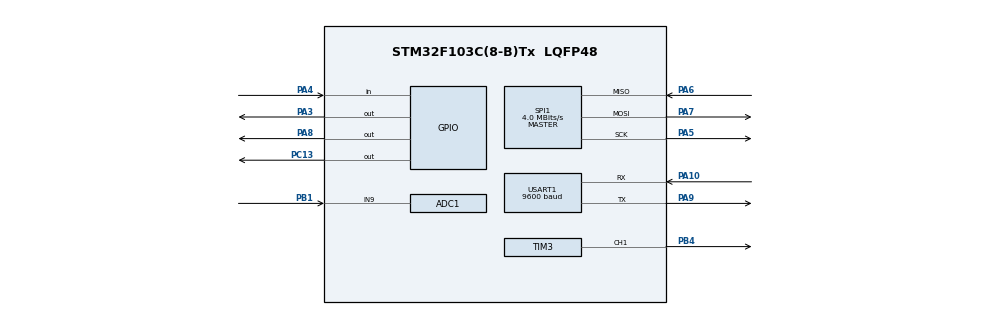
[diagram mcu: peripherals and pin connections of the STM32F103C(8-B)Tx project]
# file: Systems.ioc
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ADC1.Channel-0\#ChannelRegularConversion=ADC_CHANNEL_9
ADC1.NbrOfConversionFlag=1
ADC1.Rank-0\#ChannelRegularConversion=1
ADC1.SamplingTime-0\#ChannelRegularConversion=ADC_SAMPLETIME_1CYCLE_5
ADC1.master=1
Mcu.Family=STM32F1
Mcu.Name=STM32F103C(8-B)Tx
Mcu.Package=LQFP48
NVIC.PriorityGroup=NVIC_PRIORITYGROUP_4
NVIC.TIM1_UP_IRQn=true\:15\:0\:false\:false\:true\:false\:true
NVIC.TimeBase=TIM1_UP_IRQn
NVIC.TimeBaseIP=TIM1
PA10.Mode=Asynchronous
PA10.Signal=USART1_RX
PA13.Mode=Serial_Wire
PA13.Signal=SYS_JTMS-SWDIO
PA14.Mode=Serial_Wire
PA14.Signal=SYS_JTCK-SWCLK
PA3.Signal=GPIO_Output
PA4.Signal=GPIO_Input
PA5.Mode=Full_Duplex_Master
PA5.Signal=SPI1_SCK
PA6.Mode=Full_Duplex_Master
PA6.Signal=SPI1_MISO
PA7.Mode=Full_Duplex_Master
PA7.Signal=SPI1_MOSI
PA8.Signal=GPIO_Output
PA9.Mode=Asynchronous
PA9.Signal=USART1_TX
PB0.Signal=S_TIM3_CH3
PB1.Signal=ADCx_IN9
PB4.Signal=S_TIM3_CH1
PC13-TAMPER-RTC.Signal=GPIO_Output
ProjectManager.HeapSize=0x200
ProjectManager.StackSize=0x400
ProjectManager.TargetToolchain=STM32CubeIDE
RCC.APB1Freq_Value=8000000
RCC.APB2Freq_Value=8000000
SH.ADCx_IN9.0=ADC1_IN9,IN9
SH.S_TIM3_CH1.0=TIM3_CH1,PWM Generation1 CH1
SH.S_TIM3_CH3.0=TIM3_CH3
SPI1.CalculateBaudRate=4.0 MBits/s
SPI1.Direction=SPI_DIRECTION_2LINES
SPI1.Mode=SPI_MODE_MASTER
SPI1.VirtualType=VM_MASTER
TIM2.Prescaler=7
TIM3.Channel-PWM\ Generation1\ CH1=TIM_CHANNEL_1
TIM3.CounterMode=TIM_COUNTERMODE_DOWN
TIM3.Period=255
TIM3.Prescaler=7
TIM4.CounterMode=TIM_COUNTERMODE_DOWN
TIM4.Prescaler=7999
USART1.BaudRate=9600
USART1.VirtualMode=VM_ASYNC
VP_SYS_VS_tim1.Mode=TIM1
VP_TIM2_VS_ClockSourceINT.Mode=Internal
VP_TIM3_VS_ClockSourceINT.Mode=Internal
VP_TIM4_VS_ClockSourceINT.Mode=Internal
board=custom

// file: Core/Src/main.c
/* USER CODE BEGIN Header */
/**
  ******************************************************************************
  * @file           : main.c
  * @brief          : Main program body
  ******************************************************************************
  * @attention
  *
  * <h2><center>&copy; Copyright (c) 2022 STMicroelectronics.
  * All rights reserved.</center></h2>
  *
  * This software component is licensed by ST under BSD 3-Clause license,
  * the "License"; You may not use this file except in compliance with the
  * License. You may obtain a copy of the License at:
  *                        opensource.org/licenses/BSD-3-Clause
  *
  ******************************************************************************
  */
/* USER CODE END Header */
#include "main.h"

/* USER CODE BEGIN Includes */
#include <string.h>
#include <stdio.h>
#include "ultrasonic.h"
#include "PWM.h"
/* USER CODE END Includes */

ADC_HandleTypeDef hadc1;

SPI_HandleTypeDef hspi1;

TIM_HandleTypeDef htim2;
TIM_HandleTypeDef htim3;
TIM_HandleTypeDef htim4;

UART_HandleTypeDef huart1;

void SystemClock_Config(void);
static void MX_GPIO_Init(void);
static void MX_SPI1_Init(void);
static void MX_TIM3_Init(void);
static void MX_USART1_UART_Init(void);
static void MX_ADC1_Init(void);
static void MX_TIM2_Init(void);
static void MX_TIM4_Init(void);

/* USER CODE BEGIN 0 */
uint16_t readValue;
/* USER CODE END 0 */

int main(void)
{
  /* USER CODE BEGIN 1 */
  char msg[10];
  /* USER CODE END 1 */

  /* MCU Configuration--------------------------------------------------------*/

  /* Reset of all peripherals, Initializes the Flash interface and the Systick. */
  HAL_Init();

  /* Configure the system clock */
  SystemClock_Config();

  /* Initialize all configured peripherals */
  MX_GPIO_Init();
  MX_SPI1_Init();
  MX_TIM3_Init();
  MX_USART1_UART_Init();
  MX_ADC1_Init();
  MX_TIM2_Init();
  MX_TIM4_Init();
  /* USER CODE BEGIN 2 */
  US_vidInit(&htim2);

  //  PWM_vidInit(&htim3, TIM_CHANNEL_3);
  //HAL_TIM_PWM_Start(&htim3, TIM_CHANNEL_3);

  /* USER CODE END 2 */

  /* Infinite loop */
  /* USER CODE BEGIN WHILE */
  while (1)
  {

    /*
	     sprintf(msg, "%hu\r\n",Value1);
	      HAL_UART_Transmit(&huart1, (uint8_t *)msg, strlen(msg), HAL_MAX_DELAY);
	      HAL_Delay(1);
	      sprintf(msg, "%hu\r\n",Value2);
	     	      HAL_UART_Transmit(&huart1, (uint8_t *)msg, strlen(msg), HAL_MAX_DELAY);
	        HAL_Delay(1);
*/

    //  PWM_vidStart(50);
    //uint8_t RxByte  ;
    uint8_t TxByte = US_u8CalculateDistance();
    //	        HAL_GPIO_WritePin(GPIOA, GPIO_PIN_8, GPIO_PIN_RESET);
    //	            HAL_SPI_TransmitReceive(&hspi1, &TxByte, &RxByte, 1, HAL_MAX_DELAY);
    //
    //	            HAL_GPIO_WritePin(GPIOA, GPIO_PIN_8, GPIO_PIN_SET);
    //	     sprintf(msg, "%hu\r\n",RxByte);
    sprintf(msg, "%hu\r\n", TxByte);
    HAL_UART_Transmit(&huart1, (uint8_t *)msg, strlen(msg), HAL_MAX_DELAY);
    HAL_Delay(1000);

    //	     dutyCycle =(uint16_t) (255 * 20)/100;
    //
    //	     __HAL_TIM_SET_COMPARE(&htim3, TIM_CHANNEL_3, dutyCycle);
    HAL_GPIO_TogglePin(GPIOC, GPIO_PIN_13);

    /* USER CODE END WHILE */

  }
}

void SystemClock_Config(void)
{
  RCC_OscInitTypeDef RCC_OscInitStruct = {0};
  RCC_ClkInitTypeDef RCC_ClkInitStruct = {0};
  RCC_PeriphCLKInitTypeDef PeriphClkInit = {0};

  /** Initializes the RCC Oscillators according to the specified parameters
  * in the RCC_OscInitTypeDef structure.
  */
  RCC_OscInitStruct.OscillatorType = RCC_OSCILLATORTYPE_HSI;
  RCC_OscInitStruct.HSIState = RCC_HSI_ON;
  RCC_OscInitStruct.HSICalibrationValue = RCC_HSICALIBRATION_DEFAULT;
  RCC_OscInitStruct.PLL.PLLState = RCC_PLL_NONE;
  if (HAL_RCC_OscConfig(&RCC_OscInitStruct) != HAL_OK)
  {
    Error_Handler();
  }
  /** Initializes the CPU, AHB and APB buses clocks
  */
  RCC_ClkInitStruct.ClockType = RCC_CLOCKTYPE_HCLK | RCC_CLOCKTYPE_SYSCLK | RCC_CLOCKTYPE_PCLK1 | RCC_CLOCKTYPE_PCLK2;
  RCC_ClkInitStruct.SYSCLKSource = RCC_SYSCLKSOURCE_HSI;
  RCC_ClkInitStruct.AHBCLKDivider = RCC_SYSCLK_DIV1;
  RCC_ClkInitStruct.APB1CLKDivider = RCC_HCLK_DIV1;
  RCC_ClkInitStruct.APB2CLKDivider = RCC_HCLK_DIV1;

  if (HAL_RCC_ClockConfig(&RCC_ClkInitStruct, FLASH_LATENCY_0) != HAL_OK)
  {
    Error_Handler();
  }
  PeriphClkInit.PeriphClockSelection = RCC_PERIPHCLK_ADC;
  PeriphClkInit.AdcClockSelection = RCC_ADCPCLK2_DIV2;
  if (HAL_RCCEx_PeriphCLKConfig(&PeriphClkInit) != HAL_OK)
  {
    Error_Handler();
  }
}

static void MX_ADC1_Init(void)
{

  ADC_ChannelConfTypeDef sConfig = {0};

  /** Common config
  */
  hadc1.Instance = ADC1;
  hadc1.Init.ScanConvMode = ADC_SCAN_DISABLE;
  hadc1.Init.ContinuousConvMode = DISABLE;
  hadc1.Init.DiscontinuousConvMode = DISABLE;
  hadc1.Init.ExternalTrigConv = ADC_SOFTWARE_START;
  hadc1.Init.DataAlign = ADC_DATAALIGN_RIGHT;
  hadc1.Init.NbrOfConversion = 1;
  if (HAL_ADC_Init(&hadc1) != HAL_OK)
  {
    Error_Handler();
  }
  /** Configure Regular Channel
  */
  sConfig.Channel = ADC_CHANNEL_9;
  sConfig.Rank = ADC_REGULAR_RANK_1;
  sConfig.SamplingTime = ADC_SAMPLETIME_1CYCLE_5;
  if (HAL_ADC_ConfigChannel(&hadc1, &sConfig) != HAL_OK)
  {
    Error_Handler();
  }
}

static void MX_SPI1_Init(void)
{

  /* SPI1 parameter configuration*/
  hspi1.Instance = SPI1;
  hspi1.Init.Mode = SPI_MODE_MASTER;
  hspi1.Init.Direction = SPI_DIRECTION_2LINES;
  hspi1.Init.DataSize = SPI_DATASIZE_8BIT;
  hspi1.Init.CLKPolarity = SPI_POLARITY_LOW;
  hspi1.Init.CLKPhase = SPI_PHASE_1EDGE;
  hspi1.Init.NSS = SPI_NSS_SOFT;
  hspi1.Init.BaudRatePrescaler = SPI_BAUDRATEPRESCALER_2;
  hspi1.Init.FirstBit = SPI_FIRSTBIT_MSB;
  hspi1.Init.TIMode = SPI_TIMODE_DISABLE;
  hspi1.Init.CRCCalculation = SPI_CRCCALCULATION_DISABLE;
  hspi1.Init.CRCPolynomial = 10;
  if (HAL_SPI_Init(&hspi1) != HAL_OK)
  {
    Error_Handler();
  }
}

static void MX_TIM2_Init(void)
{

  TIM_ClockConfigTypeDef sClockSourceConfig = {0};
  TIM_MasterConfigTypeDef sMasterConfig = {0};

  htim2.Instance = TIM2;
  htim2.Init.Prescaler = 7;
  htim2.Init.CounterMode = TIM_COUNTERMODE_UP;
  htim2.Init.Period = 65535;
  htim2.Init.ClockDivision = TIM_CLOCKDIVISION_DIV1;
  htim2.Init.AutoReloadPreload = TIM_AUTORELOAD_PRELOAD_DISABLE;
  if (HAL_TIM_Base_Init(&htim2) != HAL_OK)
  {
    Error_Handler();
  }
  sClockSourceConfig.ClockSource = TIM_CLOCKSOURCE_INTERNAL;
  if (HAL_TIM_ConfigClockSource(&htim2, &sClockSourceConfig) != HAL_OK)
  {
    Error_Handler();
  }
  sMasterConfig.MasterOutputTrigger = TIM_TRGO_RESET;
  sMasterConfig.MasterSlaveMode = TIM_MASTERSLAVEMODE_DISABLE;
  if (HAL_TIMEx_MasterConfigSynchronization(&htim2, &sMasterConfig) != HAL_OK)
  {
    Error_Handler();
  }
}

static void MX_TIM3_Init(void)
{

  TIM_ClockConfigTypeDef sClockSourceConfig = {0};
  TIM_MasterConfigTypeDef sMasterConfig = {0};

  htim3.Instance = TIM3;
  htim3.Init.Prescaler = 7;
  htim3.Init.CounterMode = TIM_COUNTERMODE_DOWN;
  htim3.Init.Period = 255;
  htim3.Init.ClockDivision = TIM_CLOCKDIVISION_DIV1;
  htim3.Init.AutoReloadPreload = TIM_AUTORELOAD_PRELOAD_DISABLE;
  if (HAL_TIM_Base_Init(&htim3) != HAL_OK)
  {
    Error_Handler();
  }
  sClockSourceConfig.ClockSource = TIM_CLOCKSOURCE_INTERNAL;
  if (HAL_TIM_ConfigClockSource(&htim3, &sClockSourceConfig) != HAL_OK)
  {
    Error_Handler();
  }
  sMasterConfig.MasterOutputTrigger = TIM_TRGO_RESET;
  sMasterConfig.MasterSlaveMode = TIM_MASTERSLAVEMODE_DISABLE;
  if (HAL_TIMEx_MasterConfigSynchronization(&htim3, &sMasterConfig) != HAL_OK)
  {
    Error_Handler();
  }
}

static void MX_TIM4_Init(void)
{

  TIM_ClockConfigTypeDef sClockSourceConfig = {0};
  TIM_MasterConfigTypeDef sMasterConfig = {0};

  htim4.Instance = TIM4;
  htim4.Init.Prescaler = 0;
  htim4.Init.CounterMode = TIM_COUNTERMODE_UP;
  htim4.Init.Period = 65535;
  htim4.Init.ClockDivision = TIM_CLOCKDIVISION_DIV1;
  htim4.Init.AutoReloadPreload = TIM_AUTORELOAD_PRELOAD_DISABLE;
  if (HAL_TIM_Base_Init(&htim4) != HAL_OK)
  {
    Error_Handler();
  }
  sClockSourceConfig.ClockSource = TIM_CLOCKSOURCE_INTERNAL;
  if (HAL_TIM_ConfigClockSource(&htim4, &sClockSourceConfig) != HAL_OK)
  {
    Error_Handler();
  }
  sMasterConfig.MasterOutputTrigger = TIM_TRGO_RESET;
  sMasterConfig.MasterSlaveMode = TIM_MASTERSLAVEMODE_DISABLE;
  if (HAL_TIMEx_MasterConfigSynchronization(&htim4, &sMasterConfig) != HAL_OK)
  {
    Error_Handler();
  }
}

static void MX_USART1_UART_Init(void)
{

  huart1.Instance = USART1;
  huart1.Init.BaudRate = 9600;
  huart1.Init.WordLength = UART_WORDLENGTH_8B;
  huart1.Init.StopBits = UART_STOPBITS_1;
  huart1.Init.Parity = UART_PARITY_NONE;
  huart1.Init.Mode = UART_MODE_TX_RX;
  huart1.Init.HwFlowCtl = UART_HWCONTROL_NONE;
  huart1.Init.OverSampling = UART_OVERSAMPLING_16;
  if (HAL_UART_Init(&huart1) != HAL_OK)
  {
    Error_Handler();
  }
}

static void MX_GPIO_Init(void)
{
  GPIO_InitTypeDef GPIO_InitStruct = {0};

  /* GPIO Ports Clock Enable */
  __HAL_RCC_GPIOC_CLK_ENABLE();
  __HAL_RCC_GPIOA_CLK_ENABLE();
  __HAL_RCC_GPIOB_CLK_ENABLE();

  /*Configure GPIO pin Output Level */
  HAL_GPIO_WritePin(GPIOC, GPIO_PIN_13, GPIO_PIN_RESET);

  /*Configure GPIO pin Output Level */
  HAL_GPIO_WritePin(GPIOA, GPIO_PIN_3 | GPIO_PIN_8, GPIO_PIN_RESET);

  /*Configure GPIO pin : PC13 */
  GPIO_InitStruct.Pin = GPIO_PIN_13;
  GPIO_InitStruct.Mode = GPIO_MODE_OUTPUT_PP;
  GPIO_InitStruct.Pull = GPIO_NOPULL;
  GPIO_InitStruct.Speed = GPIO_SPEED_FREQ_LOW;
  HAL_GPIO_Init(GPIOC, &GPIO_InitStruct);

  /*Configure GPIO pins : PA3 PA8 */
  GPIO_InitStruct.Pin = GPIO_PIN_3 | GPIO_PIN_8;
  GPIO_InitStruct.Mode = GPIO_MODE_OUTPUT_PP;
  GPIO_InitStruct.Pull = GPIO_NOPULL;
  GPIO_InitStruct.Speed = GPIO_SPEED_FREQ_LOW;
  HAL_GPIO_Init(GPIOA, &GPIO_InitStruct);

  /*Configure GPIO pin : PA4 */
  GPIO_InitStruct.Pin = GPIO_PIN_4;
  GPIO_InitStruct.Mode = GPIO_MODE_INPUT;
  GPIO_InitStruct.Pull = GPIO_NOPULL;
  HAL_GPIO_Init(GPIOA, &GPIO_InitStruct);
}

void HAL_TIM_PeriodElapsedCallback(TIM_HandleTypeDef *htim)
{
  if (htim->Instance == TIM1)
  {
    HAL_IncTick();
  }
}

void Error_Handler(void)
{
  __disable_irq();
  while (1)
  {
  }
}

/************************ (C) COPYRIGHT STMicroelectronics *****END OF FILE****/
